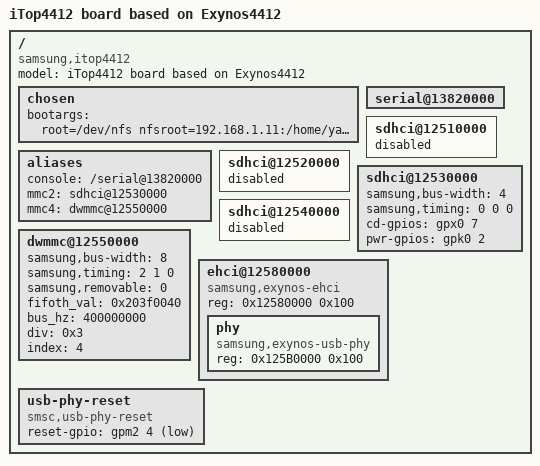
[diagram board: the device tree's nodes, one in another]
/*
 * Samsung's Exynos4210 based Origen board device tree source
 *
 * Copyright (c) 2014 Samsung Electronics Co., Ltd.
 *		http://www.samsung.com
 *
 * SPDX-License-Identifier:	GPL-2.0+
 */

/dts-v1/;
#include "skeleton.dtsi"
#include "exynos4412.dtsi"
#include <dt-bindings/gpio/gpio.h>

/ {
	model = "iTop4412 board based on Exynos4412";
	compatible = "samsung,itop4412", "samsung,exynos4412";

	chosen {
		bootargs ="root=/dev/nfs nfsroot=192.168.1.11:/home/yang/workspace/nfs/rootfs rw clk_ignore_unused console=ttySAC2,115200 init=/linuxrc  ip=192.168.1.22";
	};

	aliases {
//		serial0 = "/serial@13800000";
		console = "/serial@13820000";
		mmc2 = "sdhci@12530000";
		mmc4 = "dwmmc@12550000";
	};
	
	serial@13820000 {
		status = "okay";
	};

	sdhci@12510000 {
		status = "disabled";
	};

	sdhci@12520000 {
		status = "disabled";
	};

	sdhci@12530000 {
		samsung,bus-width = <4>;
		samsung,timing = <0 0 0>;
		cd-gpios = <&gpx0 7 0>;
		pwr-gpios = <&gpk0 2 0>;
	};

	sdhci@12540000 {
		status = "disabled";
	};

	dwmmc@12550000 {
		samsung,bus-width = <8>;
		samsung,timing = <2 1 0>;
		samsung,removable = <0>;
		fifoth_val = <0x203f0040>;
		bus_hz = <400000000>;
		div = <0x3>;
		index = <4>;
	};

	ehci@12580000 {
		compatible = "samsung,exynos-ehci";
		reg = <0x12580000 0x100>;
		#address-cells = <1>;
		#size-cells = <1>;
		phy {
			compatible = "samsung,exynos-usb-phy";
			reg = <0x125B0000 0x100>;
		};
	};
	
	usb-phy-reset {
		compatible = "smsc,usb-phy-reset";
		reset-gpio = <&gpm2 4 GPIO_ACTIVE_LOW>;
	};

};
